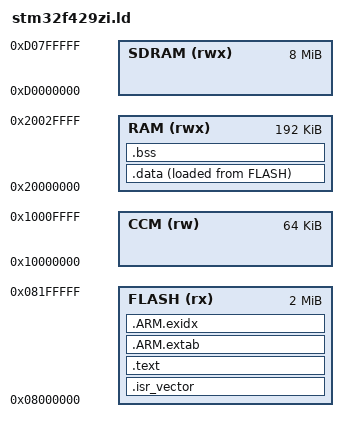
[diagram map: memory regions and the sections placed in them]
ENTRY(Reset_Handler)

MEMORY
{
    FLASH (rx) : ORIGIN = 0x08000000, LENGTH = 2048K
    RAM   (rwx): ORIGIN = 0x20000000, LENGTH = 192K
    CCM   (rw) : ORIGIN = 0x10000000, LENGTH = 64K
    SDRAM (rwx): ORIGIN = 0xD0000000, LENGTH = 8M
}

_estack = ORIGIN(RAM) + LENGTH(RAM);

SECTIONS
{
    .isr_vector :
    {
        KEEP(*(.isr_vector))
    } > FLASH

    .text :
    {
        *(.text*)
        *(.rodata*)

        KEEP(*(.init))
        KEEP(*(.fini))

        . = ALIGN(4);
        PROVIDE_HIDDEN (__preinit_array_start = .);
        KEEP (*(.preinit_array))
        PROVIDE_HIDDEN (__preinit_array_end = .);

        . = ALIGN(4);
        PROVIDE_HIDDEN (__init_array_start = .);
        KEEP (*(SORT(.init_array.*)))
        KEEP (*(.init_array))
        PROVIDE_HIDDEN (__init_array_end = .);

        . = ALIGN(4);
        PROVIDE_HIDDEN (__fini_array_start = .);
        KEEP (*(.fini_array))
        KEEP (*(SORT(.fini_array.*)))
        PROVIDE_HIDDEN (__fini_array_end = .);

        . = ALIGN(4);
    } > FLASH

    .ARM.extab : { *(.ARM.extab* .gnu.linkonce.armextab.*) } > FLASH
    .ARM.exidx :
    {
        __exidx_start = .;
        *(.ARM.exidx*)
        __exidx_end = .;
    } > FLASH

    .data :
    {
        _sdata = .;
        *(.data*)
        . = ALIGN(4);
        _edata = .;
    } > RAM AT > FLASH
    _sidata = LOADADDR(.data);

    .bss :
    {
        _sbss = .;
        *(.bss*)
        *(COMMON)
        . = ALIGN(4);
        _ebss = .;
    } > RAM

    end = .;
    _end = .;
}
